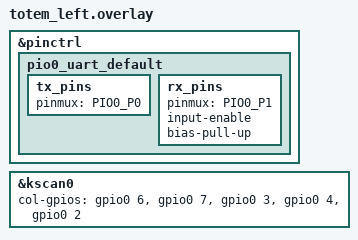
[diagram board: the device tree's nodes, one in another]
/*
 * Copyright (c) 2022 The ZMK Contributors
 *
 * SPDX-License-Identifier: MIT
 */

#include "totem.dtsi"
#include <dt-bindings/pinctrl/rpi-pico-rp2040-pinctrl.h>

&pinctrl {
    pio0_uart_default: pio0_uart_default {
        tx_pins {
            /* configure P0 as UART0 TX */
            pinmux = <PIO0_P0>;
            };
        rx_pins {
            /* configure P1 as UART0 RX */
            pinmux = <PIO0_P1>;
            input-enable;
            bias-pull-up;
        };
    };
};

&kscan0 {
    col-gpios
        = <&gpio0 6 GPIO_ACTIVE_HIGH>
        , <&gpio0 7 GPIO_ACTIVE_HIGH>
        , <&gpio0 3 GPIO_ACTIVE_HIGH>
        , <&gpio0 4 GPIO_ACTIVE_HIGH>
        , <&gpio0 2 GPIO_ACTIVE_HIGH>
        ;
};
